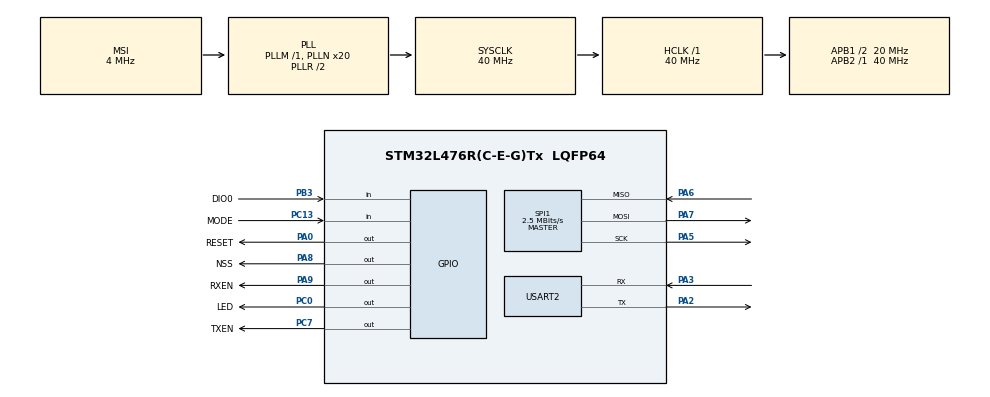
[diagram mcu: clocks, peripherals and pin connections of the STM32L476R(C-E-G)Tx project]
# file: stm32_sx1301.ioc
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Mcu.Family=STM32L4
Mcu.Name=STM32L476R(C-E-G)Tx
Mcu.Package=LQFP64
NVIC.PriorityGroup=NVIC_PRIORITYGROUP_4
PA0.GPIO_Label=RESET
PA0.Signal=GPIO_Output
PA13\ (JTMS-SWDIO).Mode=Serial_Wire
PA13\ (JTMS-SWDIO).Signal=SYS_JTMS-SWDIO
PA14\ (JTCK-SWCLK).Mode=Serial_Wire
PA14\ (JTCK-SWCLK).Signal=SYS_JTCK-SWCLK
PA2.Mode=Asynchronous
PA2.Signal=USART2_TX
PA3.Mode=Asynchronous
PA3.Signal=USART2_RX
PA5.Mode=Full_Duplex_Master
PA5.Signal=SPI1_SCK
PA6.Mode=Full_Duplex_Master
PA6.Signal=SPI1_MISO
PA7.Mode=Full_Duplex_Master
PA7.Signal=SPI1_MOSI
PA8.GPIO_Label=NSS
PA8.Signal=GPIO_Output
PA9.GPIO_Label=RXEN
PA9.Signal=GPIO_Output
PB3\ (JTDO-TRACESWO).GPIO_Label=DIO0
PB3\ (JTDO-TRACESWO).Signal=GPIO_Input
PC0.GPIO_Label=LED
PC0.Signal=GPIO_Output
PC13.GPIO_Label=MODE
PC13.Signal=GPIO_Input
PC14-OSC32_IN\ (PC14).Mode=LSE-External-Oscillator
PC14-OSC32_IN\ (PC14).Signal=RCC_OSC32_IN
PC15-OSC32_OUT\ (PC15).Mode=LSE-External-Oscillator
PC15-OSC32_OUT\ (PC15).Signal=RCC_OSC32_OUT
PC7.GPIO_Label=TXEN
PC7.Signal=GPIO_Output
ProjectManager.HeapSize=0x200
ProjectManager.StackSize=0x400
ProjectManager.TargetToolchain=EWARM V7
RCC.AHBFreq_Value=40000000
RCC.APB1CLKDivider=RCC_HCLK_DIV2
RCC.APB1Freq_Value=20000000
RCC.APB1TimFreq_Value=40000000
RCC.APB2Freq_Value=40000000
RCC.APB2TimFreq_Value=40000000
RCC.CortexFreq_Value=40000000
RCC.HCLKFreq_Value=40000000
RCC.HSE_VALUE=8000000
RCC.HSI_VALUE=16000000
RCC.MSI_VALUE=4000000
RCC.PLLN=20
RCC.PREFETCH_ENABLE=1
RCC.SYSCLKFreq_VALUE=40000000
RCC.SYSCLKSource=RCC_SYSCLKSOURCE_PLLCLK
RCC.VCOOutputFreq_Value=80000000
SPI1.BaudRatePrescaler=SPI_BAUDRATEPRESCALER_16
SPI1.CalculateBaudRate=2.5 MBits/s
SPI1.DataSize=SPI_DATASIZE_8BIT
SPI1.Direction=SPI_DIRECTION_2LINES
SPI1.Mode=SPI_MODE_MASTER
SPI1.VirtualType=VM_MASTER
USART2.VirtualMode-Asynchronous=VM_ASYNC
board=custom

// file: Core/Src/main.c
/* USER CODE BEGIN Header */
/**
  ******************************************************************************
  * @file           : main.c
  * @brief          : Main program body
  ******************************************************************************
  * @attention
  *
  * <h2><center>&copy; Copyright (c) 2022 STMicroelectronics.
  * All rights reserved.</center></h2>
  *
  * This software component is licensed by ST under BSD 3-Clause license,
  * the "License"; You may not use this file except in compliance with the
  * License. You may obtain a copy of the License at:
  *                        opensource.org/licenses/BSD-3-Clause
  *
  ******************************************************************************
  */
/* USER CODE END Header */
#include "main.h"

/* USER CODE BEGIN Includes */
#include <stdio.h>
#include "sx1301_app.h"
/* USER CODE END Includes */

SPI_HandleTypeDef hspi1;

UART_HandleTypeDef huart2;

void SystemClock_Config(void);
static void MX_GPIO_Init(void);
static void MX_USART2_UART_Init(void);
static void MX_SPI1_Init(void);

/* USER CODE BEGIN 0 */
int fputc(int ch, FILE *f)
{

  HAL_UART_Transmit(&huart2, (uint8_t *)&ch, 1, 1000);
  return ch;
}
void delay_m(int ms)
{
  for (int i = 0; i < ms; i++)
  {
     for (int k = 0; k < 7000; k++)
     {
       ;
     }

  }

}
/* USER CODE END 0 */

int main(void)
{

  /* MCU Configuration--------------------------------------------------------*/

  /* Reset of all peripherals, Initializes the Flash interface and the Systick. */
  HAL_Init();

  /* Configure the system clock */
  SystemClock_Config();

  /* Initialize all configured peripherals */
  MX_GPIO_Init();
  MX_USART2_UART_Init();
  MX_SPI1_Init();

  /* Infinite loop */
  /* USER CODE BEGIN WHILE */
  while (1)
  {
    //test_loragw_spi();
    test_loragw_reg();
    printf("this is sx1301 application\n");
    delay_m(200);

    /* USER CODE END WHILE */

  }
}

void SystemClock_Config(void)
{
  RCC_OscInitTypeDef RCC_OscInitStruct = {0};
  RCC_ClkInitTypeDef RCC_ClkInitStruct = {0};

  /** Configure the main internal regulator output voltage
  */
  if (HAL_PWREx_ControlVoltageScaling(PWR_REGULATOR_VOLTAGE_SCALE1) != HAL_OK)
  {
    Error_Handler();
  }
  /** Configure LSE Drive Capability
  */
  HAL_PWR_EnableBkUpAccess();
  __HAL_RCC_LSEDRIVE_CONFIG(RCC_LSEDRIVE_LOW);
  /** Initializes the RCC Oscillators according to the specified parameters
  * in the RCC_OscInitTypeDef structure.
  */
  RCC_OscInitStruct.OscillatorType = RCC_OSCILLATORTYPE_LSE|RCC_OSCILLATORTYPE_MSI;
  RCC_OscInitStruct.LSEState = RCC_LSE_ON;
  RCC_OscInitStruct.MSIState = RCC_MSI_ON;
  RCC_OscInitStruct.MSICalibrationValue = 0;
  RCC_OscInitStruct.MSIClockRange = RCC_MSIRANGE_6;
  RCC_OscInitStruct.PLL.PLLState = RCC_PLL_ON;
  RCC_OscInitStruct.PLL.PLLSource = RCC_PLLSOURCE_MSI;
  RCC_OscInitStruct.PLL.PLLM = 1;
  RCC_OscInitStruct.PLL.PLLN = 20;
  RCC_OscInitStruct.PLL.PLLP = RCC_PLLP_DIV7;
  RCC_OscInitStruct.PLL.PLLQ = RCC_PLLQ_DIV2;
  RCC_OscInitStruct.PLL.PLLR = RCC_PLLR_DIV2;
  if (HAL_RCC_OscConfig(&RCC_OscInitStruct) != HAL_OK)
  {
    Error_Handler();
  }
  /** Initializes the CPU, AHB and APB buses clocks
  */
  RCC_ClkInitStruct.ClockType = RCC_CLOCKTYPE_HCLK|RCC_CLOCKTYPE_SYSCLK
                              |RCC_CLOCKTYPE_PCLK1|RCC_CLOCKTYPE_PCLK2;
  RCC_ClkInitStruct.SYSCLKSource = RCC_SYSCLKSOURCE_PLLCLK;
  RCC_ClkInitStruct.AHBCLKDivider = RCC_SYSCLK_DIV1;
  RCC_ClkInitStruct.APB1CLKDivider = RCC_HCLK_DIV2;
  RCC_ClkInitStruct.APB2CLKDivider = RCC_HCLK_DIV1;

  if (HAL_RCC_ClockConfig(&RCC_ClkInitStruct, FLASH_LATENCY_2) != HAL_OK)
  {
    Error_Handler();
  }
  /** Enable MSI Auto calibration
  */
  HAL_RCCEx_EnableMSIPLLMode();
}

static void MX_SPI1_Init(void)
{

  /* SPI1 parameter configuration*/
  hspi1.Instance = SPI1;
  hspi1.Init.Mode = SPI_MODE_MASTER;
  hspi1.Init.Direction = SPI_DIRECTION_2LINES;
  hspi1.Init.DataSize = SPI_DATASIZE_8BIT;
  hspi1.Init.CLKPolarity = SPI_POLARITY_LOW;
  hspi1.Init.CLKPhase = SPI_PHASE_1EDGE;
  hspi1.Init.NSS = SPI_NSS_SOFT;
  hspi1.Init.BaudRatePrescaler = SPI_BAUDRATEPRESCALER_16;
  hspi1.Init.FirstBit = SPI_FIRSTBIT_MSB;
  hspi1.Init.TIMode = SPI_TIMODE_DISABLE;
  hspi1.Init.CRCCalculation = SPI_CRCCALCULATION_DISABLE;
  hspi1.Init.CRCPolynomial = 7;
  hspi1.Init.CRCLength = SPI_CRC_LENGTH_DATASIZE;
  hspi1.Init.NSSPMode = SPI_NSS_PULSE_ENABLE;
  if (HAL_SPI_Init(&hspi1) != HAL_OK)
  {
    Error_Handler();
  }

}

static void MX_USART2_UART_Init(void)
{

  huart2.Instance = USART2;
  huart2.Init.BaudRate = 115200;
  huart2.Init.WordLength = UART_WORDLENGTH_8B;
  huart2.Init.StopBits = UART_STOPBITS_1;
  huart2.Init.Parity = UART_PARITY_NONE;
  huart2.Init.Mode = UART_MODE_TX_RX;
  huart2.Init.HwFlowCtl = UART_HWCONTROL_NONE;
  huart2.Init.OverSampling = UART_OVERSAMPLING_16;
  huart2.Init.OneBitSampling = UART_ONE_BIT_SAMPLE_DISABLE;
  huart2.AdvancedInit.AdvFeatureInit = UART_ADVFEATURE_NO_INIT;
  if (HAL_UART_Init(&huart2) != HAL_OK)
  {
    Error_Handler();
  }

}

static void MX_GPIO_Init(void)
{
  GPIO_InitTypeDef GPIO_InitStruct = {0};

  /* GPIO Ports Clock Enable */
  __HAL_RCC_GPIOC_CLK_ENABLE();
  __HAL_RCC_GPIOA_CLK_ENABLE();
  __HAL_RCC_GPIOB_CLK_ENABLE();

  /*Configure GPIO pin Output Level */
  HAL_GPIO_WritePin(GPIOC, LED_Pin|TXEN_Pin, GPIO_PIN_RESET);

  /*Configure GPIO pin Output Level */
  HAL_GPIO_WritePin(GPIOA, RESET_Pin|NSS_Pin|RXEN_Pin, GPIO_PIN_RESET);

  /*Configure GPIO pin : MODE_Pin */
  GPIO_InitStruct.Pin = MODE_Pin;
  GPIO_InitStruct.Mode = GPIO_MODE_INPUT;
  GPIO_InitStruct.Pull = GPIO_NOPULL;
  HAL_GPIO_Init(MODE_GPIO_Port, &GPIO_InitStruct);

  /*Configure GPIO pins : LED_Pin TXEN_Pin */
  GPIO_InitStruct.Pin = LED_Pin|TXEN_Pin;
  GPIO_InitStruct.Mode = GPIO_MODE_OUTPUT_PP;
  GPIO_InitStruct.Pull = GPIO_NOPULL;
  GPIO_InitStruct.Speed = GPIO_SPEED_FREQ_LOW;
  HAL_GPIO_Init(GPIOC, &GPIO_InitStruct);

  /*Configure GPIO pins : RESET_Pin NSS_Pin RXEN_Pin */
  GPIO_InitStruct.Pin = RESET_Pin|NSS_Pin|RXEN_Pin;
  GPIO_InitStruct.Mode = GPIO_MODE_OUTPUT_PP;
  GPIO_InitStruct.Pull = GPIO_NOPULL;
  GPIO_InitStruct.Speed = GPIO_SPEED_FREQ_LOW;
  HAL_GPIO_Init(GPIOA, &GPIO_InitStruct);

  /*Configure GPIO pin : DIO0_Pin */
  GPIO_InitStruct.Pin = DIO0_Pin;
  GPIO_InitStruct.Mode = GPIO_MODE_INPUT;
  GPIO_InitStruct.Pull = GPIO_NOPULL;
  HAL_GPIO_Init(DIO0_GPIO_Port, &GPIO_InitStruct);

}

void Error_Handler(void)
{
  __disable_irq();
  while (1)
  {
  }
}

/************************ (C) COPYRIGHT STMicroelectronics *****END OF FILE****/
